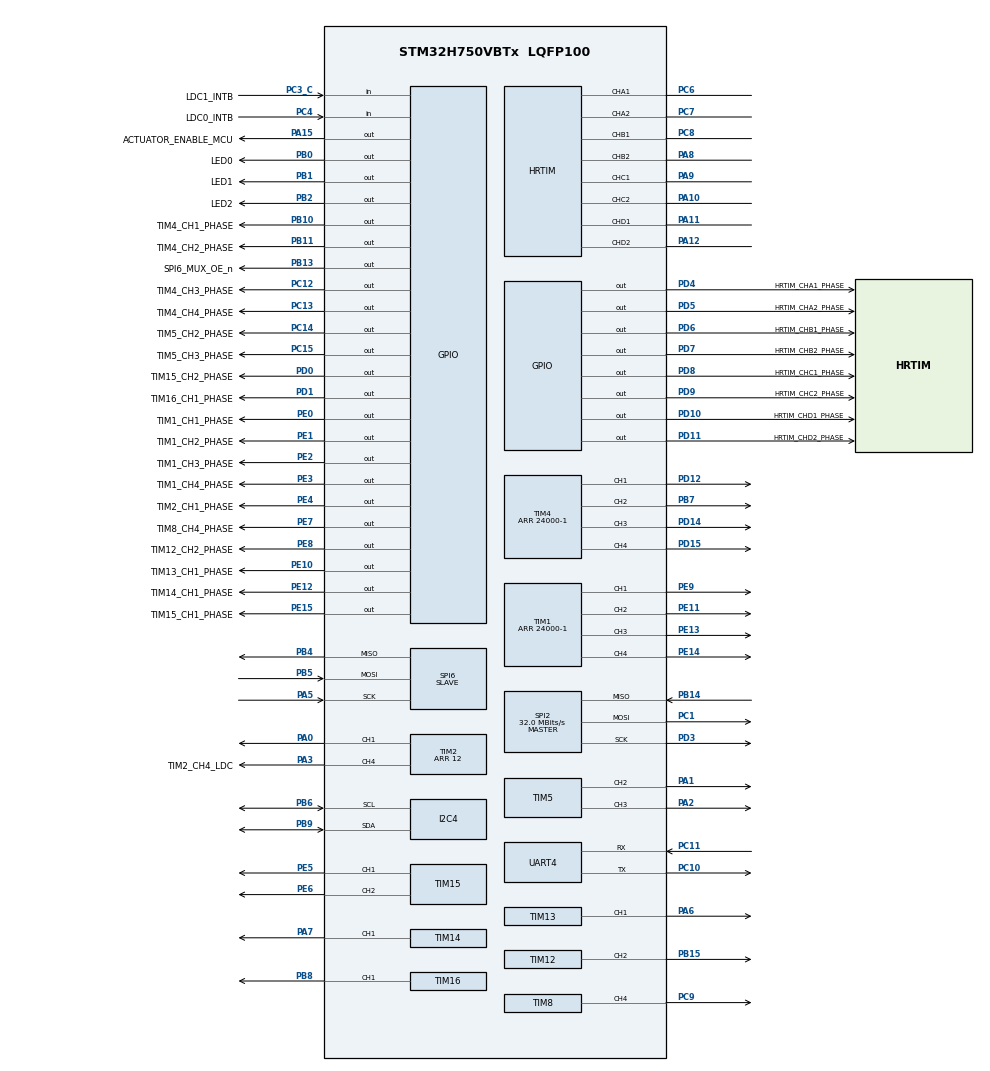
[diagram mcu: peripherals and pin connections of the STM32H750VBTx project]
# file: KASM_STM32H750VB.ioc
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HRTIM.Configuration_TD=Simple
HRTIM.Configuration_TE=Simple
HRTIM.PWMChannel_TD1=HRTIM_OUTPUT_TD1
HRTIM.Periode_TE=0xFF00
I2C4.Timing=0x307075B1
Mcu.Family=STM32H7
Mcu.Name=STM32H750VBTx
Mcu.Package=LQFP100
NVIC.PriorityGroup=NVIC_PRIORITYGROUP_4
NVIC.TIM1_UP_IRQn=true\:0\:0\:false\:false\:true\:true\:true\:true
PA0.Signal=S_TIM2_CH1_ETR
PA1.Signal=S_TIM5_CH2
PA10.Mode=Output_TC1TC2
PA10.Signal=HRTIM_CHC2
PA11.Mode=Output_TD1TD2
PA11.Signal=HRTIM_CHD1
PA12.Mode=Output_TD1TD2
PA12.Signal=HRTIM_CHD2
PA13\ (JTMS/SWDIO).Mode=Trace_Asynchronous_SW
PA13\ (JTMS/SWDIO).Signal=DEBUG_JTMS-SWDIO
PA14\ (JTCK/SWCLK).Mode=Trace_Asynchronous_SW
PA14\ (JTCK/SWCLK).Signal=DEBUG_JTCK-SWCLK
PA15\ (JTDI).GPIO_Label=ACTUATOR_ENABLE_MCU
PA15\ (JTDI).Signal=GPIO_Output
PA2.Signal=S_TIM5_CH3
PA3.GPIO_Label=TIM2_CH4_LDC
PA3.Signal=S_TIM2_CH4
PA4.Signal=SPI6_NSS
PA5.Mode=Full_Duplex_Slave
PA5.Signal=SPI6_SCK
PA6.Signal=S_TIM13_CH1
PA7.Signal=S_TIM14_CH1
PA8.Mode=Output_TB1TB2
PA8.Signal=HRTIM_CHB2
PA9.Mode=Output_TC1TC2
PA9.Signal=HRTIM_CHC1
PB0.GPIO_Label=LED0
PB0.Signal=GPIO_Output
PB1.GPIO_Label=LED1
PB1.Signal=GPIO_Output
PB10.GPIO_Label=TIM4_CH1_PHASE
PB10.Signal=GPIO_Output
PB11.GPIO_Label=TIM4_CH2_PHASE
PB11.Signal=GPIO_Output
PB12.Signal=SPI2_NSS
PB13.GPIO_Label=SPI6_MUX_OE_n
PB13.Signal=GPIO_Output
PB14.Mode=Full_Duplex_Master
PB14.Signal=SPI2_MISO
PB15.Signal=S_TIM12_CH2
PB2.GPIO_Label=LED2
PB2.Signal=GPIO_Output
PB3\ (JTDO/TRACESWO).Mode=Trace_Asynchronous_SW
PB3\ (JTDO/TRACESWO).Signal=DEBUG_JTDO-SWO
PB4\ (NJTRST).Mode=Full_Duplex_Slave
PB4\ (NJTRST).Signal=SPI6_MISO
PB5.Mode=Full_Duplex_Slave
PB5.Signal=SPI6_MOSI
PB6.Mode=I2C
PB6.Signal=I2C4_SCL
PB7.Signal=S_TIM4_CH2
PB8.Signal=S_TIM16_CH1
PB9.Mode=I2C
PB9.Signal=I2C4_SDA
PC0.Signal=ADCx_INP10
PC1.Mode=Full_Duplex_Master
PC1.Signal=SPI2_MOSI
PC10.Mode=Asynchronous
PC10.Signal=UART4_TX
PC11.Mode=Asynchronous
PC11.Signal=UART4_RX
PC12.GPIO_Label=TIM4_CH3_PHASE
PC12.Signal=GPIO_Output
PC13.GPIO_Label=TIM4_CH4_PHASE
PC13.Signal=GPIO_Output
PC14-OSC32_IN\ (OSC32_IN).GPIO_Label=TIM5_CH2_PHASE
PC14-OSC32_IN\ (OSC32_IN).Signal=GPIO_Output
PC15-OSC32_OUT\ (OSC32_OUT).GPIO_Label=TIM5_CH3_PHASE
PC15-OSC32_OUT\ (OSC32_OUT).Signal=GPIO_Output
PC3_C.GPIO_Label=LDC1_INTB
PC3_C.Signal=GPIO_Input
PC4.GPIO_Label=LDC0_INTB
PC4.Signal=GPIO_Input
PC6.Mode=Output_TA1TA2
PC6.Signal=HRTIM_CHA1
PC7.Mode=Output_TA1TA2
PC7.Signal=HRTIM_CHA2
PC8.Mode=Output_TB1TB2
PC8.Signal=HRTIM_CHB1
PC9.Signal=S_TIM8_CH4
PD0.GPIO_Label=TIM15_CH2_PHASE
PD0.Signal=GPIO_Output
PD1.GPIO_Label=TIM16_CH1_PHASE
PD1.Signal=GPIO_Output
PD10.GPIO_Label=HRTIM_CHD1_PHASE
PD10.Signal=GPIO_Output
PD11.GPIO_Label=HRTIM_CHD2_PHASE
PD11.Signal=GPIO_Output
PD12.Signal=S_TIM4_CH1
PD14.Signal=S_TIM4_CH3
PD15.Signal=S_TIM4_CH4
PD3.Mode=Full_Duplex_Master
PD3.Signal=SPI2_SCK
PD4.GPIO_Label=HRTIM_CHA1_PHASE
PD4.Signal=GPIO_Output
PD5.GPIO_Label=HRTIM_CHA2_PHASE
PD5.Signal=GPIO_Output
PD6.GPIO_Label=HRTIM_CHB1_PHASE
PD6.Signal=GPIO_Output
PD7.GPIO_Label=HRTIM_CHB2_PHASE
PD7.Signal=GPIO_Output
PD8.GPIO_Label=HRTIM_CHC1_PHASE
PD8.Signal=GPIO_Output
PD9.GPIO_Label=HRTIM_CHC2_PHASE
PD9.Signal=GPIO_Output
PE0.GPIO_Label=TIM1_CH1_PHASE
PE0.Signal=GPIO_Output
PE1.GPIO_Label=TIM1_CH2_PHASE
PE1.Signal=GPIO_Output
PE10.GPIO_Label=TIM13_CH1_PHASE
PE10.Signal=GPIO_Output
PE11.Signal=S_TIM1_CH2
PE12.GPIO_Label=TIM14_CH1_PHASE
PE12.Signal=GPIO_Output
PE13.Signal=S_TIM1_CH3
PE14.Signal=S_TIM1_CH4
PE15.GPIO_Label=TIM15_CH1_PHASE
PE15.Signal=GPIO_Output
PE2.GPIO_Label=TIM1_CH3_PHASE
PE2.Signal=GPIO_Output
PE3.GPIO_Label=TIM1_CH4_PHASE
PE3.Signal=GPIO_Output
PE4.GPIO_Label=TIM2_CH1_PHASE
PE4.Signal=GPIO_Output
PE5.Signal=S_TIM15_CH1
PE6.Signal=S_TIM15_CH2
PE7.GPIO_Label=TIM8_CH4_PHASE
PE7.Signal=GPIO_Output
PE8.GPIO_Label=TIM12_CH2_PHASE
PE8.Signal=GPIO_Output
PE9.Signal=S_TIM1_CH1
PH0-OSC_IN\ (PH0).Mode=HSE-External-Oscillator
PH0-OSC_IN\ (PH0).Signal=RCC_OSC_IN
PH1-OSC_OUT\ (PH1).Mode=HSE-External-Oscillator
PH1-OSC_OUT\ (PH1).Signal=RCC_OSC_OUT
ProjectManager.HeapSize=0x200
ProjectManager.StackSize=0x400
ProjectManager.TargetToolchain=STM32CubeIDE
RCC.ADCFreq_Value=75000000
RCC.APB1Freq_Value=120000000
RCC.APB2Freq_Value=120000000
RCC.APB3Freq_Value=120000000
RCC.APB4Freq_Value=120000000
RCC.CortexFreq_Value=480000000
RCC.D1PPRE=RCC_APB3_DIV2
RCC.D2PPRE1=RCC_APB1_DIV2
RCC.D2PPRE2=RCC_APB2_DIV2
RCC.D3PPRE=RCC_APB4_DIV2
RCC.DIVM1=2
RCC.DIVM2=2
RCC.DIVN1=80
RCC.DIVN2=12
RCC.DIVQ1=15
RCC.HCLKFreq_Value=240000000
RCC.HPRE=RCC_HCLK_DIV2
RCC.HSE_VALUE=24000000
RCC.PLL2FRACN=4096
RCC.PLL3FRACN=0
RCC.PLLFRACN=0
RCC.PLLSourceVirtual=RCC_PLLSOURCE_HSE
RCC.SYSCLKFreq_VALUE=480000000
RCC.SYSCLKSource=RCC_SYSCLKSOURCE_PLLCLK
RCC.USBFreq_Value=64000000
SH.ADCx_INP10.0=ADC2_INP10
SH.S_TIM12_CH2.0=TIM12_CH2,PWM Generation2 CH2
SH.S_TIM13_CH1.0=TIM13_CH1,PWM Generation1 CH1
SH.S_TIM14_CH1.0=TIM14_CH1,PWM Generation1 CH1
SH.S_TIM15_CH1.0=TIM15_CH1,PWM Generation1 CH1
SH.S_TIM15_CH2.0=TIM15_CH2,PWM Generation2 CH2
SH.S_TIM16_CH1.0=TIM16_CH1,PWM Generation1 CH1
SH.S_TIM1_CH1.0=TIM1_CH1,PWM Generation1 CH1
SH.S_TIM1_CH2.0=TIM1_CH2,PWM Generation2 CH2
SH.S_TIM1_CH3.0=TIM1_CH3,PWM Generation3 CH3
SH.S_TIM1_CH4.0=TIM1_CH4,PWM Generation4 CH4
SH.S_TIM2_CH1_ETR.0=TIM2_CH1,PWM Generation1 CH1
SH.S_TIM2_CH4.0=TIM2_CH4,PWM Generation4 CH4
SH.S_TIM4_CH1.0=TIM4_CH1,PWM Generation1 CH1
SH.S_TIM4_CH2.0=TIM4_CH2,PWM Generation2 CH2
SH.S_TIM4_CH3.0=TIM4_CH3,PWM Generation3 CH3
SH.S_TIM4_CH4.0=TIM4_CH4,PWM Generation4 CH4
SH.S_TIM5_CH2.0=TIM5_CH2,PWM Generation2 CH2
SH.S_TIM5_CH3.0=TIM5_CH3,PWM Generation3 CH3
SH.S_TIM8_CH4.0=TIM8_CH4,PWM Generation4 CH4
SPI2.CalculateBaudRate=32.0 MBits/s
SPI2.Direction=SPI_DIRECTION_2LINES
SPI2.Mode=SPI_MODE_MASTER
SPI2.VirtualType=VM_MASTER
SPI6.DataSize=SPI_DATASIZE_16BIT
SPI6.Direction=SPI_DIRECTION_2LINES
SPI6.Mode=SPI_MODE_SLAVE
SPI6.VirtualType=VM_SLAVE
TIM1.Channel-PWM\ Generation1\ CH1=TIM_CHANNEL_1
TIM1.Channel-PWM\ Generation2\ CH2=TIM_CHANNEL_2
TIM1.Channel-PWM\ Generation3\ CH3=TIM_CHANNEL_3
TIM1.Channel-PWM\ Generation4\ CH4=TIM_CHANNEL_4
TIM1.Period=24000-1
TIM12.Channel-PWM\ Generation2\ CH2=TIM_CHANNEL_2
TIM13.Channel=TIM_CHANNEL_1
TIM14.Channel=TIM_CHANNEL_1
TIM15.Channel-PWM\ Generation1\ CH1=TIM_CHANNEL_1
TIM15.Channel-PWM\ Generation2\ CH2=TIM_CHANNEL_2
TIM16.Channel=TIM_CHANNEL_1
TIM2.Channel-PWM\ Generation1\ CH1=TIM_CHANNEL_1
TIM2.Channel-PWM\ Generation4\ CH4=TIM_CHANNEL_4
TIM2.Period=12
TIM2.Pulse-PWM\ Generation1\ CH1=3
TIM2.Pulse-PWM\ Generation4\ CH4=6
TIM4.Channel-PWM\ Generation1\ CH1=TIM_CHANNEL_1
TIM4.Channel-PWM\ Generation2\ CH2=TIM_CHANNEL_2
TIM4.Channel-PWM\ Generation3\ CH3=TIM_CHANNEL_3
TIM4.Channel-PWM\ Generation4\ CH4=TIM_CHANNEL_4
TIM4.Period=24000-1
TIM5.Channel-PWM\ Generation2\ CH2=TIM_CHANNEL_2
TIM5.Channel-PWM\ Generation3\ CH3=TIM_CHANNEL_3
TIM8.Channel-PWM\ Generation4\ CH4=TIM_CHANNEL_4
VP_HRTIM_VS_hrtimMasterTimerNoOutput.Mode=MasterTimer
VP_HRTIM_VS_hrtimTimerENoOutput.Mode=No_output_TE
VP_LPTIM1_VS_LPTIM_counterModeInternalClock.Mode=Counts__internal_clock_event_00
VP_LPTIM2_VS_LPTIM_counterModeInternalClock.Mode=Counts__internal_clock_event_00
VP_LPTIM3_VS_LPTIM_counterModeInternalClock.Mode=Counts__internal_clock_event_00
VP_TIM13_VS_ClockSourceINT.Mode=Enable_Timer
VP_TIM14_VS_ClockSourceINT.Mode=Enable_Timer
VP_TIM16_VS_ClockSourceINT.Mode=Enable_Timer
VP_TIM1_VS_ClockSourceINT.Mode=Internal
VP_TIM4_VS_ClockSourceINT.Mode=Internal
board=custom

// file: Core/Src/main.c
/* USER CODE BEGIN Header */
/**
  ******************************************************************************
  * @file           : main.c
  * @brief          : Main program body
  ******************************************************************************
  * @attention
  *
  * Copyright (c) 2024 STMicroelectronics.
  * All rights reserved.
  *
  * This software is licensed under terms that can be found in the LICENSE file
  * in the root directory of this software component.
  * If no LICENSE file comes with this software, it is provided AS-IS.
  *
  ******************************************************************************
  */
/* USER CODE END Header */
#include "main.h"

/* USER CODE BEGIN Includes */
#include "ldc1614.h"

/* USER CODE END Includes */

/* USER CODE BEGIN PD */

#define PERIOD 24000
//Converts timer ticks to time scaling factor
#define PERIOD_SCALE (1.0/24000)
#define TICK_SCALE (1.0/240000000)

//Circular buffer characteristics
#define BUFFER_LENGTH 2048
#define MESSAGE_LENGTH 128

//Parameters for sorting/storing actuator commands
#define CMD_LENGTH 26*2
#define NUM_ACTUATORS 26

#define TRUE 1
#define FALSE 0
#define ONESEC 10000
#define TWOSEC 20000

/* USER CODE END PD */

HRTIM_HandleTypeDef hhrtim;

I2C_HandleTypeDef hi2c4;

LPTIM_HandleTypeDef hlptim1;
LPTIM_HandleTypeDef hlptim2;
LPTIM_HandleTypeDef hlptim3;

SPI_HandleTypeDef hspi2;
SPI_HandleTypeDef hspi6;

TIM_HandleTypeDef htim1;
TIM_HandleTypeDef htim2;
TIM_HandleTypeDef htim4;
TIM_HandleTypeDef htim5;
TIM_HandleTypeDef htim8;
TIM_HandleTypeDef htim12;
TIM_HandleTypeDef htim13;
TIM_HandleTypeDef htim14;
TIM_HandleTypeDef htim15;
TIM_HandleTypeDef htim16;

UART_HandleTypeDef huart4;

/* USER CODE BEGIN PV */

static const double VSS = 1.8; // fixed by PCB design
uint8_t ctrl_tmr_expired = FALSE; //controller update flag
static double ref=0;// reference (input) for control loop

/* USER CODE END PV */

void SystemClock_Config(void);
static void MX_GPIO_Init(void);
static void MX_HRTIM_Init(void);
static void MX_I2C4_Init(void);
static void MX_LPTIM1_Init(void);
static void MX_LPTIM2_Init(void);
static void MX_LPTIM3_Init(void);
static void MX_SPI2_Init(void);
static void MX_TIM1_Init(void);
static void MX_TIM2_Init(void);
static void MX_TIM4_Init(void);
static void MX_TIM5_Init(void);
static void MX_TIM8_Init(void);
static void MX_TIM12_Init(void);
static void MX_TIM13_Init(void);
static void MX_TIM14_Init(void);
static void MX_TIM15_Init(void);
static void MX_TIM16_Init(void);
static void MX_UART4_Init(void);
static void MX_SPI6_Init(void);
/* USER CODE BEGIN PFP */
static void control_update(double ref);
static uint16_t calc_dutycycle(double cmd, double vss);

/* USER CODE END PFP */

int main(void)
{

  /* USER CODE BEGIN 1 */
	int channel = 0;
	int L_uH = 72;
	int C_pF = 330;
	volatile uint32_t readings[NSAMPS] = {0};
	int ct = 0;
	int cycle_count = 0;

	uint8_t data[2] = {0};

	LDC1614 dev;

  /* USER CODE END 1 */

  /* MCU Configuration--------------------------------------------------------*/

  /* Reset of all peripherals, Initializes the Flash interface and the Systick. */
  HAL_Init();

  /* Configure the system clock */
  SystemClock_Config();

  /* Initialize all configured peripherals */
  MX_GPIO_Init();
  MX_HRTIM_Init();
  MX_I2C4_Init();
  MX_LPTIM1_Init();
  MX_LPTIM2_Init();
  MX_LPTIM3_Init();
  MX_SPI2_Init();
  MX_TIM1_Init();
  MX_TIM2_Init();
  MX_TIM4_Init();
  MX_TIM5_Init();
  MX_TIM8_Init();
  MX_TIM12_Init();
  MX_TIM13_Init();
  MX_TIM14_Init();
  MX_TIM15_Init();
  MX_TIM16_Init();
  MX_UART4_Init();
  MX_SPI6_Init();
  /* USER CODE BEGIN 2 */
  /* enable VSS */
  HAL_GPIO_WritePin(ACTUATOR_ENABLE_MCU_GPIO_Port, ACTUATOR_ENABLE_MCU_Pin, GPIO_PIN_SET);

  // Timer 1 initialization
  // Timer 1 serves as the main timer and is interrupted by period end
  HAL_TIM_Base_Start_IT(&htim1);
  HAL_TIM_PWM_Start(&htim1, TIM_CHANNEL_1);
  HAL_TIM_PWM_Start(&htim1, TIM_CHANNEL_2);
  HAL_TIM_PWM_Start(&htim1, TIM_CHANNEL_3);
  HAL_TIM_PWM_Start(&htim1, TIM_CHANNEL_4);
  HAL_GPIO_WritePin(TIM1_CH1_PHASE_GPIO_Port, TIM1_CH1_PHASE_Pin, GPIO_PIN_SET);
  HAL_GPIO_WritePin(TIM1_CH2_PHASE_GPIO_Port, TIM1_CH2_PHASE_Pin, GPIO_PIN_SET);
  HAL_GPIO_WritePin(TIM1_CH3_PHASE_GPIO_Port, TIM1_CH3_PHASE_Pin, GPIO_PIN_SET);
  HAL_GPIO_WritePin(TIM1_CH4_PHASE_GPIO_Port, TIM1_CH4_PHASE_Pin, GPIO_PIN_SET);

  //Timer 2 ch 4 is used as an oscillator for the eddy current sensor
  HAL_TIM_Base_Start(&htim2);
  HAL_TIM_PWM_Start(&htim2, TIM_CHANNEL_4);

  // End Timer 1

  ldc1614_init(&dev, &hi2c4, channel, L_uH, C_pF);

  ldc1614_read_reg(&dev, LDC1614_DEVICE_ID, data);
  ldc1614_read_reg(&dev, LDC1614_STATUS, data);

  /* USER CODE END 2 */

  /* Infinite loop */
  /* USER CODE BEGIN WHILE */
  while (1)
  {
	  if(ctrl_tmr_expired == TRUE) {
		  control_update(ref);
		  cycle_count += 1;
//		  if (cycle_count == 1000) {
//			  cycle_count = 0; // reset cycle counter

			  data[1] = 0;
			  ldc1614_read_reg(&dev, LDC1614_STATUS, data); // check for new data
			  if((data[1] & 0x08) !=0){ // if new data available
				  readings[ct] = ldc1614_get_ch0_reading(&dev); // get a sample
				  ct++; // increment sample counter
			  }
			  if(ct == NSAMPS) {
				  ct = 0; // reset sample counter
			  }
//		  }

	  }

    /* USER CODE END WHILE */

  }
}

void SystemClock_Config(void)
{
  RCC_OscInitTypeDef RCC_OscInitStruct = {0};
  RCC_ClkInitTypeDef RCC_ClkInitStruct = {0};

  /** Supply configuration update enable
  */
  HAL_PWREx_ConfigSupply(PWR_LDO_SUPPLY);

  /** Configure the main internal regulator output voltage
  */
  __HAL_PWR_VOLTAGESCALING_CONFIG(PWR_REGULATOR_VOLTAGE_SCALE1);

  while(!__HAL_PWR_GET_FLAG(PWR_FLAG_VOSRDY)) {}

  __HAL_RCC_SYSCFG_CLK_ENABLE();
  __HAL_PWR_VOLTAGESCALING_CONFIG(PWR_REGULATOR_VOLTAGE_SCALE0);

  while(!__HAL_PWR_GET_FLAG(PWR_FLAG_VOSRDY)) {}

  /** Initializes the RCC Oscillators according to the specified parameters
  * in the RCC_OscInitTypeDef structure.
  */
  RCC_OscInitStruct.OscillatorType = RCC_OSCILLATORTYPE_HSE;
  RCC_OscInitStruct.HSEState = RCC_HSE_ON;
  RCC_OscInitStruct.PLL.PLLState = RCC_PLL_ON;
  RCC_OscInitStruct.PLL.PLLSource = RCC_PLLSOURCE_HSE;
  RCC_OscInitStruct.PLL.PLLM = 2;
  RCC_OscInitStruct.PLL.PLLN = 80;
  RCC_OscInitStruct.PLL.PLLP = 2;
  RCC_OscInitStruct.PLL.PLLQ = 15;
  RCC_OscInitStruct.PLL.PLLR = 2;
  RCC_OscInitStruct.PLL.PLLRGE = RCC_PLL1VCIRANGE_3;
  RCC_OscInitStruct.PLL.PLLVCOSEL = RCC_PLL1VCOWIDE;
  RCC_OscInitStruct.PLL.PLLFRACN = 0;
  if (HAL_RCC_OscConfig(&RCC_OscInitStruct) != HAL_OK)
  {
    Error_Handler();
  }

  /** Initializes the CPU, AHB and APB buses clocks
  */
  RCC_ClkInitStruct.ClockType = RCC_CLOCKTYPE_HCLK|RCC_CLOCKTYPE_SYSCLK
                              |RCC_CLOCKTYPE_PCLK1|RCC_CLOCKTYPE_PCLK2
                              |RCC_CLOCKTYPE_D3PCLK1|RCC_CLOCKTYPE_D1PCLK1;
  RCC_ClkInitStruct.SYSCLKSource = RCC_SYSCLKSOURCE_PLLCLK;
  RCC_ClkInitStruct.SYSCLKDivider = RCC_SYSCLK_DIV1;
  RCC_ClkInitStruct.AHBCLKDivider = RCC_HCLK_DIV2;
  RCC_ClkInitStruct.APB3CLKDivider = RCC_APB3_DIV2;
  RCC_ClkInitStruct.APB1CLKDivider = RCC_APB1_DIV2;
  RCC_ClkInitStruct.APB2CLKDivider = RCC_APB2_DIV2;
  RCC_ClkInitStruct.APB4CLKDivider = RCC_APB4_DIV2;

  if (HAL_RCC_ClockConfig(&RCC_ClkInitStruct, FLASH_LATENCY_4) != HAL_OK)
  {
    Error_Handler();
  }
}

static void MX_HRTIM_Init(void)
{

  HRTIM_TimeBaseCfgTypeDef pTimeBaseCfg = {0};
  HRTIM_TimerCfgTypeDef pTimerCfg = {0};
  HRTIM_OutputCfgTypeDef pOutputCfg = {0};
  HRTIM_SimplePWMChannelCfgTypeDef pSimplePWMChannelCfg = {0};

  hhrtim.Instance = HRTIM1;
  hhrtim.Init.HRTIMInterruptResquests = HRTIM_IT_NONE;
  hhrtim.Init.SyncOptions = HRTIM_SYNCOPTION_NONE;
  if (HAL_HRTIM_Init(&hhrtim) != HAL_OK)
  {
    Error_Handler();
  }
  pTimeBaseCfg.Period = 0xFFFD;
  pTimeBaseCfg.RepetitionCounter = 0x00;
  pTimeBaseCfg.PrescalerRatio = HRTIM_PRESCALERRATIO_DIV1;
  pTimeBaseCfg.Mode = HRTIM_MODE_CONTINUOUS;
  if (HAL_HRTIM_TimeBaseConfig(&hhrtim, HRTIM_TIMERINDEX_MASTER, &pTimeBaseCfg) != HAL_OK)
  {
    Error_Handler();
  }
  pTimerCfg.InterruptRequests = HRTIM_MASTER_IT_NONE;
  pTimerCfg.DMARequests = HRTIM_MASTER_DMA_NONE;
  pTimerCfg.DMASrcAddress = 0x0000;
  pTimerCfg.DMADstAddress = 0x0000;
  pTimerCfg.DMASize = 0x1;
  pTimerCfg.HalfModeEnable = HRTIM_HALFMODE_DISABLED;
  pTimerCfg.StartOnSync = HRTIM_SYNCSTART_DISABLED;
  pTimerCfg.ResetOnSync = HRTIM_SYNCRESET_DISABLED;
  pTimerCfg.DACSynchro = HRTIM_DACSYNC_NONE;
  pTimerCfg.PreloadEnable = HRTIM_PRELOAD_DISABLED;
  pTimerCfg.UpdateGating = HRTIM_UPDATEGATING_INDEPENDENT;
  pTimerCfg.BurstMode = HRTIM_TIMERBURSTMODE_MAINTAINCLOCK;
  pTimerCfg.RepetitionUpdate = HRTIM_UPDATEONREPETITION_DISABLED;
  if (HAL_HRTIM_WaveformTimerConfig(&hhrtim, HRTIM_TIMERINDEX_MASTER, &pTimerCfg) != HAL_OK)
  {
    Error_Handler();
  }
  if (HAL_HRTIM_TimeBaseConfig(&hhrtim, HRTIM_TIMERINDEX_TIMER_A, &pTimeBaseCfg) != HAL_OK)
  {
    Error_Handler();
  }
  pTimerCfg.InterruptRequests = HRTIM_TIM_IT_NONE;
  pTimerCfg.DMARequests = HRTIM_TIM_DMA_NONE;
  pTimerCfg.PushPull = HRTIM_TIMPUSHPULLMODE_DISABLED;
  pTimerCfg.FaultEnable = HRTIM_TIMFAULTENABLE_NONE;
  pTimerCfg.FaultLock = HRTIM_TIMFAULTLOCK_READWRITE;
  pTimerCfg.DeadTimeInsertion = HRTIM_TIMDEADTIMEINSERTION_DISABLED;
  pTimerCfg.DelayedProtectionMode = HRTIM_TIMER_A_B_C_DELAYEDPROTECTION_DISABLED;
  pTimerCfg.UpdateTrigger = HRTIM_TIMUPDATETRIGGER_NONE;
  pTimerCfg.ResetTrigger = HRTIM_TIMRESETTRIGGER_NONE;
  pTimerCfg.ResetUpdate = HRTIM_TIMUPDATEONRESET_DISABLED;
  if (HAL_HRTIM_WaveformTimerConfig(&hhrtim, HRTIM_TIMERINDEX_TIMER_A, &pTimerCfg) != HAL_OK)
  {
    Error_Handler();
  }
  if (HAL_HRTIM_WaveformTimerConfig(&hhrtim, HRTIM_TIMERINDEX_TIMER_B, &pTimerCfg) != HAL_OK)
  {
    Error_Handler();
  }
  if (HAL_HRTIM_WaveformTimerConfig(&hhrtim, HRTIM_TIMERINDEX_TIMER_C, &pTimerCfg) != HAL_OK)
  {
    Error_Handler();
  }
  pOutputCfg.Polarity = HRTIM_OUTPUTPOLARITY_HIGH;
  pOutputCfg.SetSource = HRTIM_OUTPUTSET_NONE;
  pOutputCfg.ResetSource = HRTIM_OUTPUTRESET_NONE;
  pOutputCfg.IdleMode = HRTIM_OUTPUTIDLEMODE_NONE;
  pOutputCfg.IdleLevel = HRTIM_OUTPUTIDLELEVEL_INACTIVE;
  pOutputCfg.FaultLevel = HRTIM_OUTPUTFAULTLEVEL_NONE;
  pOutputCfg.ChopperModeEnable = HRTIM_OUTPUTCHOPPERMODE_DISABLED;
  pOutputCfg.BurstModeEntryDelayed = HRTIM_OUTPUTBURSTMODEENTRY_REGULAR;
  if (HAL_HRTIM_WaveformOutputConfig(&hhrtim, HRTIM_TIMERINDEX_TIMER_A, HRTIM_OUTPUT_TA1, &pOutputCfg) != HAL_OK)
  {
    Error_Handler();
  }
  if (HAL_HRTIM_WaveformOutputConfig(&hhrtim, HRTIM_TIMERINDEX_TIMER_B, HRTIM_OUTPUT_TB1, &pOutputCfg) != HAL_OK)
  {
    Error_Handler();
  }
  if (HAL_HRTIM_WaveformOutputConfig(&hhrtim, HRTIM_TIMERINDEX_TIMER_C, HRTIM_OUTPUT_TC1, &pOutputCfg) != HAL_OK)
  {
    Error_Handler();
  }
  if (HAL_HRTIM_WaveformOutputConfig(&hhrtim, HRTIM_TIMERINDEX_TIMER_A, HRTIM_OUTPUT_TA2, &pOutputCfg) != HAL_OK)
  {
    Error_Handler();
  }
  if (HAL_HRTIM_WaveformOutputConfig(&hhrtim, HRTIM_TIMERINDEX_TIMER_B, HRTIM_OUTPUT_TB2, &pOutputCfg) != HAL_OK)
  {
    Error_Handler();
  }
  if (HAL_HRTIM_WaveformOutputConfig(&hhrtim, HRTIM_TIMERINDEX_TIMER_C, HRTIM_OUTPUT_TC2, &pOutputCfg) != HAL_OK)
  {
    Error_Handler();
  }
  if (HAL_HRTIM_TimeBaseConfig(&hhrtim, HRTIM_TIMERINDEX_TIMER_B, &pTimeBaseCfg) != HAL_OK)
  {
    Error_Handler();
  }
  if (HAL_HRTIM_TimeBaseConfig(&hhrtim, HRTIM_TIMERINDEX_TIMER_C, &pTimeBaseCfg) != HAL_OK)
  {
    Error_Handler();
  }
  if (HAL_HRTIM_TimeBaseConfig(&hhrtim, HRTIM_TIMERINDEX_TIMER_D, &pTimeBaseCfg) != HAL_OK)
  {
    Error_Handler();
  }
  pSimplePWMChannelCfg.Pulse = 0xFFFD;
  pSimplePWMChannelCfg.Polarity = HRTIM_OUTPUTPOLARITY_HIGH;
  pSimplePWMChannelCfg.IdleLevel = HRTIM_OUTPUTIDLELEVEL_INACTIVE;
  if (HAL_HRTIM_SimplePWMChannelConfig(&hhrtim, HRTIM_TIMERINDEX_TIMER_D, HRTIM_OUTPUT_TD1, &pSimplePWMChannelCfg) != HAL_OK)
  {
    Error_Handler();
  }
  pTimeBaseCfg.Period = 0xFF00;
  if (HAL_HRTIM_TimeBaseConfig(&hhrtim, HRTIM_TIMERINDEX_TIMER_E, &pTimeBaseCfg) != HAL_OK)
  {
    Error_Handler();
  }
  HAL_HRTIM_MspPostInit(&hhrtim);

}

static void MX_I2C4_Init(void)
{

  hi2c4.Instance = I2C4;
  hi2c4.Init.Timing = 0x307075B1;
  hi2c4.Init.OwnAddress1 = 0;
  hi2c4.Init.AddressingMode = I2C_ADDRESSINGMODE_7BIT;
  hi2c4.Init.DualAddressMode = I2C_DUALADDRESS_DISABLE;
  hi2c4.Init.OwnAddress2 = 0;
  hi2c4.Init.OwnAddress2Masks = I2C_OA2_NOMASK;
  hi2c4.Init.GeneralCallMode = I2C_GENERALCALL_DISABLE;
  hi2c4.Init.NoStretchMode = I2C_NOSTRETCH_DISABLE;
  if (HAL_I2C_Init(&hi2c4) != HAL_OK)
  {
    Error_Handler();
  }

  /** Configure Analogue filter
  */
  if (HAL_I2CEx_ConfigAnalogFilter(&hi2c4, I2C_ANALOGFILTER_ENABLE) != HAL_OK)
  {
    Error_Handler();
  }

  /** Configure Digital filter
  */
  if (HAL_I2CEx_ConfigDigitalFilter(&hi2c4, 0) != HAL_OK)
  {
    Error_Handler();
  }

}

static void MX_LPTIM1_Init(void)
{

  hlptim1.Instance = LPTIM1;
  hlptim1.Init.Clock.Source = LPTIM_CLOCKSOURCE_APBCLOCK_LPOSC;
  hlptim1.Init.Clock.Prescaler = LPTIM_PRESCALER_DIV1;
  hlptim1.Init.Trigger.Source = LPTIM_TRIGSOURCE_SOFTWARE;
  hlptim1.Init.OutputPolarity = LPTIM_OUTPUTPOLARITY_HIGH;
  hlptim1.Init.UpdateMode = LPTIM_UPDATE_IMMEDIATE;
  hlptim1.Init.CounterSource = LPTIM_COUNTERSOURCE_INTERNAL;
  hlptim1.Init.Input1Source = LPTIM_INPUT1SOURCE_GPIO;
  hlptim1.Init.Input2Source = LPTIM_INPUT2SOURCE_GPIO;
  if (HAL_LPTIM_Init(&hlptim1) != HAL_OK)
  {
    Error_Handler();
  }

}

static void MX_LPTIM2_Init(void)
{

  hlptim2.Instance = LPTIM2;
  hlptim2.Init.Clock.Source = LPTIM_CLOCKSOURCE_APBCLOCK_LPOSC;
  hlptim2.Init.Clock.Prescaler = LPTIM_PRESCALER_DIV1;
  hlptim2.Init.Trigger.Source = LPTIM_TRIGSOURCE_SOFTWARE;
  hlptim2.Init.OutputPolarity = LPTIM_OUTPUTPOLARITY_HIGH;
  hlptim2.Init.UpdateMode = LPTIM_UPDATE_IMMEDIATE;
  hlptim2.Init.CounterSource = LPTIM_COUNTERSOURCE_INTERNAL;
  hlptim2.Init.Input1Source = LPTIM_INPUT1SOURCE_GPIO;
  hlptim2.Init.Input2Source = LPTIM_INPUT2SOURCE_GPIO;
  if (HAL_LPTIM_Init(&hlptim2) != HAL_OK)
  {
    Error_Handler();
  }

}

static void MX_LPTIM3_Init(void)
{

  hlptim3.Instance = LPTIM3;
  hlptim3.Init.Clock.Source = LPTIM_CLOCKSOURCE_APBCLOCK_LPOSC;
  hlptim3.Init.Clock.Prescaler = LPTIM_PRESCALER_DIV1;
  hlptim3.Init.Trigger.Source = LPTIM_TRIGSOURCE_SOFTWARE;
  hlptim3.Init.OutputPolarity = LPTIM_OUTPUTPOLARITY_HIGH;
  hlptim3.Init.UpdateMode = LPTIM_UPDATE_IMMEDIATE;
  hlptim3.Init.CounterSource = LPTIM_COUNTERSOURCE_INTERNAL;
  hlptim3.Init.Input1Source = LPTIM_INPUT1SOURCE_GPIO;
  if (HAL_LPTIM_Init(&hlptim3) != HAL_OK)
  {
    Error_Handler();
  }

}

static void MX_SPI2_Init(void)
{

  /* SPI2 parameter configuration*/
  hspi2.Instance = SPI2;
  hspi2.Init.Mode = SPI_MODE_MASTER;
  hspi2.Init.Direction = SPI_DIRECTION_2LINES;
  hspi2.Init.DataSize = SPI_DATASIZE_4BIT;
  hspi2.Init.CLKPolarity = SPI_POLARITY_LOW;
  hspi2.Init.CLKPhase = SPI_PHASE_1EDGE;
  hspi2.Init.NSS = SPI_NSS_SOFT;
  hspi2.Init.BaudRatePrescaler = SPI_BAUDRATEPRESCALER_2;
  hspi2.Init.FirstBit = SPI_FIRSTBIT_MSB;
  hspi2.Init.TIMode = SPI_TIMODE_DISABLE;
  hspi2.Init.CRCCalculation = SPI_CRCCALCULATION_DISABLE;
  hspi2.Init.CRCPolynomial = 0x0;
  hspi2.Init.NSSPMode = SPI_NSS_PULSE_ENABLE;
  hspi2.Init.NSSPolarity = SPI_NSS_POLARITY_LOW;
  hspi2.Init.FifoThreshold = SPI_FIFO_THRESHOLD_01DATA;
  hspi2.Init.TxCRCInitializationPattern = SPI_CRC_INITIALIZATION_ALL_ZERO_PATTERN;
  hspi2.Init.RxCRCInitializationPattern = SPI_CRC_INITIALIZATION_ALL_ZERO_PATTERN;
  hspi2.Init.MasterSSIdleness = SPI_MASTER_SS_IDLENESS_00CYCLE;
  hspi2.Init.MasterInterDataIdleness = SPI_MASTER_INTERDATA_IDLENESS_00CYCLE;
  hspi2.Init.MasterReceiverAutoSusp = SPI_MASTER_RX_AUTOSUSP_DISABLE;
  hspi2.Init.MasterKeepIOState = SPI_MASTER_KEEP_IO_STATE_DISABLE;
  hspi2.Init.IOSwap = SPI_IO_SWAP_DISABLE;
  if (HAL_SPI_Init(&hspi2) != HAL_OK)
  {
    Error_Handler();
  }

}

static void MX_SPI6_Init(void)
{

  /* SPI6 parameter configuration*/
  hspi6.Instance = SPI6;
  hspi6.Init.Mode = SPI_MODE_SLAVE;
  hspi6.Init.Direction = SPI_DIRECTION_2LINES;
  hspi6.Init.DataSize = SPI_DATASIZE_16BIT;
  hspi6.Init.CLKPolarity = SPI_POLARITY_LOW;
  hspi6.Init.CLKPhase = SPI_PHASE_1EDGE;
  hspi6.Init.NSS = SPI_NSS_SOFT;
  hspi6.Init.FirstBit = SPI_FIRSTBIT_MSB;
  hspi6.Init.TIMode = SPI_TIMODE_DISABLE;
  hspi6.Init.CRCCalculation = SPI_CRCCALCULATION_DISABLE;
  hspi6.Init.CRCPolynomial = 0x0;
  hspi6.Init.NSSPMode = SPI_NSS_PULSE_DISABLE;
  hspi6.Init.NSSPolarity = SPI_NSS_POLARITY_LOW;
  hspi6.Init.FifoThreshold = SPI_FIFO_THRESHOLD_01DATA;
  hspi6.Init.TxCRCInitializationPattern = SPI_CRC_INITIALIZATION_ALL_ZERO_PATTERN;
  hspi6.Init.RxCRCInitializationPattern = SPI_CRC_INITIALIZATION_ALL_ZERO_PATTERN;
  hspi6.Init.MasterSSIdleness = SPI_MASTER_SS_IDLENESS_00CYCLE;
  hspi6.Init.MasterInterDataIdleness = SPI_MASTER_INTERDATA_IDLENESS_00CYCLE;
  hspi6.Init.MasterReceiverAutoSusp = SPI_MASTER_RX_AUTOSUSP_DISABLE;
  hspi6.Init.MasterKeepIOState = SPI_MASTER_KEEP_IO_STATE_DISABLE;
  hspi6.Init.IOSwap = SPI_IO_SWAP_DISABLE;
  if (HAL_SPI_Init(&hspi6) != HAL_OK)
  {
    Error_Handler();
  }

}

static void MX_TIM1_Init(void)
{

  TIM_ClockConfigTypeDef sClockSourceConfig = {0};
  TIM_MasterConfigTypeDef sMasterConfig = {0};
  TIM_OC_InitTypeDef sConfigOC = {0};
  TIM_BreakDeadTimeConfigTypeDef sBreakDeadTimeConfig = {0};

  htim1.Instance = TIM1;
  htim1.Init.Prescaler = 0;
  htim1.Init.CounterMode = TIM_COUNTERMODE_UP;
  htim1.Init.Period = 24000-1;
  htim1.Init.ClockDivision = TIM_CLOCKDIVISION_DIV1;
  htim1.Init.RepetitionCounter = 0;
  htim1.Init.AutoReloadPreload = TIM_AUTORELOAD_PRELOAD_DISABLE;
  if (HAL_TIM_Base_Init(&htim1) != HAL_OK)
  {
    Error_Handler();
  }
  sClockSourceConfig.ClockSource = TIM_CLOCKSOURCE_INTERNAL;
  if (HAL_TIM_ConfigClockSource(&htim1, &sClockSourceConfig) != HAL_OK)
  {
    Error_Handler();
  }
  if (HAL_TIM_PWM_Init(&htim1) != HAL_OK)
  {
    Error_Handler();
  }
  sMasterConfig.MasterOutputTrigger = TIM_TRGO_RESET;
  sMasterConfig.MasterOutputTrigger2 = TIM_TRGO2_RESET;
  sMasterConfig.MasterSlaveMode = TIM_MASTERSLAVEMODE_DISABLE;
  if (HAL_TIMEx_MasterConfigSynchronization(&htim1, &sMasterConfig) != HAL_OK)
  {
    Error_Handler();
  }
  sConfigOC.OCMode = TIM_OCMODE_PWM1;
  sConfigOC.Pulse = 0;
  sConfigOC.OCPolarity = TIM_OCPOLARITY_HIGH;
  sConfigOC.OCNPolarity = TIM_OCNPOLARITY_HIGH;
  sConfigOC.OCFastMode = TIM_OCFAST_DISABLE;
  sConfigOC.OCIdleState = TIM_OCIDLESTATE_RESET;
  sConfigOC.OCNIdleState = TIM_OCNIDLESTATE_RESET;
  if (HAL_TIM_PWM_ConfigChannel(&htim1, &sConfigOC, TIM_CHANNEL_1) != HAL_OK)
  {
    Error_Handler();
  }
  if (HAL_TIM_PWM_ConfigChannel(&htim1, &sConfigOC, TIM_CHANNEL_2) != HAL_OK)
  {
    Error_Handler();
  }
  if (HAL_TIM_PWM_ConfigChannel(&htim1, &sConfigOC, TIM_CHANNEL_3) != HAL_OK)
  {
    Error_Handler();
  }
  if (HAL_TIM_PWM_ConfigChannel(&htim1, &sConfigOC, TIM_CHANNEL_4) != HAL_OK)
  {
    Error_Handler();
  }
  sBreakDeadTimeConfig.OffStateRunMode = TIM_OSSR_DISABLE;
  sBreakDeadTimeConfig.OffStateIDLEMode = TIM_OSSI_DISABLE;
  sBreakDeadTimeConfig.LockLevel = TIM_LOCKLEVEL_OFF;
  sBreakDeadTimeConfig.DeadTime = 0;
  sBreakDeadTimeConfig.BreakState = TIM_BREAK_DISABLE;
  sBreakDeadTimeConfig.BreakPolarity = TIM_BREAKPOLARITY_HIGH;
  sBreakDeadTimeConfig.BreakFilter = 0;
  sBreakDeadTimeConfig.Break2State = TIM_BREAK2_DISABLE;
  sBreakDeadTimeConfig.Break2Polarity = TIM_BREAK2POLARITY_HIGH;
  sBreakDeadTimeConfig.Break2Filter = 0;
  sBreakDeadTimeConfig.AutomaticOutput = TIM_AUTOMATICOUTPUT_DISABLE;
  if (HAL_TIMEx_ConfigBreakDeadTime(&htim1, &sBreakDeadTimeConfig) != HAL_OK)
  {
    Error_Handler();
  }
  HAL_TIM_MspPostInit(&htim1);

}

static void MX_TIM2_Init(void)
{

  TIM_MasterConfigTypeDef sMasterConfig = {0};
  TIM_OC_InitTypeDef sConfigOC = {0};

  htim2.Instance = TIM2;
  htim2.Init.Prescaler = 0;
  htim2.Init.CounterMode = TIM_COUNTERMODE_UP;
  htim2.Init.Period = 12;
  htim2.Init.ClockDivision = TIM_CLOCKDIVISION_DIV1;
  htim2.Init.AutoReloadPreload = TIM_AUTORELOAD_PRELOAD_DISABLE;
  if (HAL_TIM_PWM_Init(&htim2) != HAL_OK)
  {
    Error_Handler();
  }
  sMasterConfig.MasterOutputTrigger = TIM_TRGO_RESET;
  sMasterConfig.MasterSlaveMode = TIM_MASTERSLAVEMODE_DISABLE;
  if (HAL_TIMEx_MasterConfigSynchronization(&htim2, &sMasterConfig) != HAL_OK)
  {
    Error_Handler();
  }
  sConfigOC.OCMode = TIM_OCMODE_PWM1;
  sConfigOC.Pulse = 3;
  sConfigOC.OCPolarity = TIM_OCPOLARITY_HIGH;
  sConfigOC.OCFastMode = TIM_OCFAST_DISABLE;
  if (HAL_TIM_PWM_ConfigChannel(&htim2, &sConfigOC, TIM_CHANNEL_1) != HAL_OK)
  {
    Error_Handler();
  }
  sConfigOC.Pulse = 6;
  if (HAL_TIM_PWM_ConfigChannel(&htim2, &sConfigOC, TIM_CHANNEL_4) != HAL_OK)
  {
    Error_Handler();
  }
  HAL_TIM_MspPostInit(&htim2);

}

static void MX_TIM4_Init(void)
{

  TIM_ClockConfigTypeDef sClockSourceConfig = {0};
  TIM_MasterConfigTypeDef sMasterConfig = {0};
  TIM_OC_InitTypeDef sConfigOC = {0};

  htim4.Instance = TIM4;
  htim4.Init.Prescaler = 0;
  htim4.Init.CounterMode = TIM_COUNTERMODE_UP;
  htim4.Init.Period = 24000-1;
  htim4.Init.ClockDivision = TIM_CLOCKDIVISION_DIV1;
  htim4.Init.AutoReloadPreload = TIM_AUTORELOAD_PRELOAD_DISABLE;
  if (HAL_TIM_Base_Init(&htim4) != HAL_OK)
  {
    Error_Handler();
  }
  sClockSourceConfig.ClockSource = TIM_CLOCKSOURCE_INTERNAL;
  if (HAL_TIM_ConfigClockSource(&htim4, &sClockSourceConfig) != HAL_OK)
  {
    Error_Handler();
  }
  if (HAL_TIM_PWM_Init(&htim4) != HAL_OK)
  {
    Error_Handler();
  }
  sMasterConfig.MasterOutputTrigger = TIM_TRGO_RESET;
  sMasterConfig.MasterSlaveMode = TIM_MASTERSLAVEMODE_DISABLE;
  if (HAL_TIMEx_MasterConfigSynchronization(&htim4, &sMasterConfig) != HAL_OK)
  {
    Error_Handler();
  }
  sConfigOC.OCMode = TIM_OCMODE_PWM1;
  sConfigOC.Pulse = 0;
  sConfigOC.OCPolarity = TIM_OCPOLARITY_HIGH;
  sConfigOC.OCFastMode = TIM_OCFAST_DISABLE;
  if (HAL_TIM_PWM_ConfigChannel(&htim4, &sConfigOC, TIM_CHANNEL_1) != HAL_OK)
  {
    Error_Handler();
  }
  if (HAL_TIM_PWM_ConfigChannel(&htim4, &sConfigOC, TIM_CHANNEL_2) != HAL_OK)
  {
    Error_Handler();
  }
  if (HAL_TIM_PWM_ConfigChannel(&htim4, &sConfigOC, TIM_CHANNEL_3) != HAL_OK)
  {
    Error_Handler();
  }
  if (HAL_TIM_PWM_ConfigChannel(&htim4, &sConfigOC, TIM_CHANNEL_4) != HAL_OK)
  {
    Error_Handler();
  }
  HAL_TIM_MspPostInit(&htim4);

}

static void MX_TIM5_Init(void)
{

  TIM_MasterConfigTypeDef sMasterConfig = {0};
  TIM_OC_InitTypeDef sConfigOC = {0};

  htim5.Instance = TIM5;
  htim5.Init.Prescaler = 0;
  htim5.Init.CounterMode = TIM_COUNTERMODE_UP;
  htim5.Init.Period = 4294967295;
  htim5.Init.ClockDivision = TIM_CLOCKDIVISION_DIV1;
  htim5.Init.AutoReloadPreload = TIM_AUTORELOAD_PRELOAD_DISABLE;
  if (HAL_TIM_PWM_Init(&htim5) != HAL_OK)
  {
    Error_Handler();
  }
  sMasterConfig.MasterOutputTrigger = TIM_TRGO_RESET;
  sMasterConfig.MasterSlaveMode = TIM_MASTERSLAVEMODE_DISABLE;
  if (HAL_TIMEx_MasterConfigSynchronization(&htim5, &sMasterConfig) != HAL_OK)
  {
    Error_Handler();
  }
  sConfigOC.OCMode = TIM_OCMODE_PWM1;
  sConfigOC.Pulse = 0;
  sConfigOC.OCPolarity = TIM_OCPOLARITY_HIGH;
  sConfigOC.OCFastMode = TIM_OCFAST_DISABLE;
  if (HAL_TIM_PWM_ConfigChannel(&htim5, &sConfigOC, TIM_CHANNEL_2) != HAL_OK)
  {
    Error_Handler();
  }
  if (HAL_TIM_PWM_ConfigChannel(&htim5, &sConfigOC, TIM_CHANNEL_3) != HAL_OK)
  {
    Error_Handler();
  }
  HAL_TIM_MspPostInit(&htim5);

}

static void MX_TIM8_Init(void)
{

  TIM_MasterConfigTypeDef sMasterConfig = {0};
  TIM_OC_InitTypeDef sConfigOC = {0};
  TIM_BreakDeadTimeConfigTypeDef sBreakDeadTimeConfig = {0};

  htim8.Instance = TIM8;
  htim8.Init.Prescaler = 0;
  htim8.Init.CounterMode = TIM_COUNTERMODE_UP;
  htim8.Init.Period = 65535;
  htim8.Init.ClockDivision = TIM_CLOCKDIVISION_DIV1;
  htim8.Init.RepetitionCounter = 0;
  htim8.Init.AutoReloadPreload = TIM_AUTORELOAD_PRELOAD_DISABLE;
  if (HAL_TIM_PWM_Init(&htim8) != HAL_OK)
  {
    Error_Handler();
  }
  sMasterConfig.MasterOutputTrigger = TIM_TRGO_RESET;
  sMasterConfig.MasterOutputTrigger2 = TIM_TRGO2_RESET;
  sMasterConfig.MasterSlaveMode = TIM_MASTERSLAVEMODE_DISABLE;
  if (HAL_TIMEx_MasterConfigSynchronization(&htim8, &sMasterConfig) != HAL_OK)
  {
    Error_Handler();
  }
  sConfigOC.OCMode = TIM_OCMODE_PWM1;
  sConfigOC.Pulse = 0;
  sConfigOC.OCPolarity = TIM_OCPOLARITY_HIGH;
  sConfigOC.OCFastMode = TIM_OCFAST_DISABLE;
  sConfigOC.OCIdleState = TIM_OCIDLESTATE_RESET;
  sConfigOC.OCNIdleState = TIM_OCNIDLESTATE_RESET;
  if (HAL_TIM_PWM_ConfigChannel(&htim8, &sConfigOC, TIM_CHANNEL_4) != HAL_OK)
  {
    Error_Handler();
  }
  sBreakDeadTimeConfig.OffStateRunMode = TIM_OSSR_DISABLE;
  sBreakDeadTimeConfig.OffStateIDLEMode = TIM_OSSI_DISABLE;
  sBreakDeadTimeConfig.LockLevel = TIM_LOCKLEVEL_OFF;
  sBreakDeadTimeConfig.DeadTime = 0;
  sBreakDeadTimeConfig.BreakState = TIM_BREAK_DISABLE;
  sBreakDeadTimeConfig.BreakPolarity = TIM_BREAKPOLARITY_HIGH;
  sBreakDeadTimeConfig.BreakFilter = 0;
  sBreakDeadTimeConfig.Break2State = TIM_BREAK2_DISABLE;
  sBreakDeadTimeConfig.Break2Polarity = TIM_BREAK2POLARITY_HIGH;
  sBreakDeadTimeConfig.Break2Filter = 0;
  sBreakDeadTimeConfig.AutomaticOutput = TIM_AUTOMATICOUTPUT_DISABLE;
  if (HAL_TIMEx_ConfigBreakDeadTime(&htim8, &sBreakDeadTimeConfig) != HAL_OK)
  {
    Error_Handler();
  }
  HAL_TIM_MspPostInit(&htim8);

}

static void MX_TIM12_Init(void)
{

  TIM_MasterConfigTypeDef sMasterConfig = {0};
  TIM_OC_InitTypeDef sConfigOC = {0};

  htim12.Instance = TIM12;
  htim12.Init.Prescaler = 0;
  htim12.Init.CounterMode = TIM_COUNTERMODE_UP;
  htim12.Init.Period = 65535;
  htim12.Init.ClockDivision = TIM_CLOCKDIVISION_DIV1;
  htim12.Init.AutoReloadPreload = TIM_AUTORELOAD_PRELOAD_DISABLE;
  if (HAL_TIM_PWM_Init(&htim12) != HAL_OK)
  {
    Error_Handler();
  }
  sMasterConfig.MasterOutputTrigger = TIM_TRGO_RESET;
  sMasterConfig.MasterSlaveMode = TIM_MASTERSLAVEMODE_DISABLE;
  if (HAL_TIMEx_MasterConfigSynchronization(&htim12, &sMasterConfig) != HAL_OK)
  {
    Error_Handler();
  }
  sConfigOC.OCMode = TIM_OCMODE_PWM1;
  sConfigOC.Pulse = 0;
  sConfigOC.OCPolarity = TIM_OCPOLARITY_HIGH;
  sConfigOC.OCFastMode = TIM_OCFAST_DISABLE;
  if (HAL_TIM_PWM_ConfigChannel(&htim12, &sConfigOC, TIM_CHANNEL_2) != HAL_OK)
  {
    Error_Handler();
  }
  HAL_TIM_MspPostInit(&htim12);

}

static void MX_TIM13_Init(void)
{

  TIM_OC_InitTypeDef sConfigOC = {0};

  htim13.Instance = TIM13;
  htim13.Init.Prescaler = 0;
  htim13.Init.CounterMode = TIM_COUNTERMODE_UP;
  htim13.Init.Period = 65535;
  htim13.Init.ClockDivision = TIM_CLOCKDIVISION_DIV1;
  htim13.Init.AutoReloadPreload = TIM_AUTORELOAD_PRELOAD_DISABLE;
  if (HAL_TIM_Base_Init(&htim13) != HAL_OK)
  {
    Error_Handler();
  }
  if (HAL_TIM_PWM_Init(&htim13) != HAL_OK)
  {
    Error_Handler();
  }
  sConfigOC.OCMode = TIM_OCMODE_PWM1;
  sConfigOC.Pulse = 0;
  sConfigOC.OCPolarity = TIM_OCPOLARITY_HIGH;
  sConfigOC.OCFastMode = TIM_OCFAST_DISABLE;
  if (HAL_TIM_PWM_ConfigChannel(&htim13, &sConfigOC, TIM_CHANNEL_1) != HAL_OK)
  {
    Error_Handler();
  }
  HAL_TIM_MspPostInit(&htim13);

}

static void MX_TIM14_Init(void)
{

  TIM_OC_InitTypeDef sConfigOC = {0};

  htim14.Instance = TIM14;
  htim14.Init.Prescaler = 0;
  htim14.Init.CounterMode = TIM_COUNTERMODE_UP;
  htim14.Init.Period = 65535;
  htim14.Init.ClockDivision = TIM_CLOCKDIVISION_DIV1;
  htim14.Init.AutoReloadPreload = TIM_AUTORELOAD_PRELOAD_DISABLE;
  if (HAL_TIM_Base_Init(&htim14) != HAL_OK)
  {
    Error_Handler();
  }
  if (HAL_TIM_PWM_Init(&htim14) != HAL_OK)
  {
    Error_Handler();
  }
  sConfigOC.OCMode = TIM_OCMODE_PWM1;
  sConfigOC.Pulse = 0;
  sConfigOC.OCPolarity = TIM_OCPOLARITY_HIGH;
  sConfigOC.OCFastMode = TIM_OCFAST_DISABLE;
  if (HAL_TIM_PWM_ConfigChannel(&htim14, &sConfigOC, TIM_CHANNEL_1) != HAL_OK)
  {
    Error_Handler();
  }
  HAL_TIM_MspPostInit(&htim14);

}

static void MX_TIM15_Init(void)
{

  TIM_MasterConfigTypeDef sMasterConfig = {0};
  TIM_OC_InitTypeDef sConfigOC = {0};
  TIM_BreakDeadTimeConfigTypeDef sBreakDeadTimeConfig = {0};

  htim15.Instance = TIM15;
  htim15.Init.Prescaler = 0;
  htim15.Init.CounterMode = TIM_COUNTERMODE_UP;
  htim15.Init.Period = 65535;
  htim15.Init.ClockDivision = TIM_CLOCKDIVISION_DIV1;
  htim15.Init.RepetitionCounter = 0;
  htim15.Init.AutoReloadPreload = TIM_AUTORELOAD_PRELOAD_DISABLE;
  if (HAL_TIM_PWM_Init(&htim15) != HAL_OK)
  {
    Error_Handler();
  }
  sMasterConfig.MasterOutputTrigger = TIM_TRGO_RESET;
  sMasterConfig.MasterSlaveMode = TIM_MASTERSLAVEMODE_DISABLE;
  if (HAL_TIMEx_MasterConfigSynchronization(&htim15, &sMasterConfig) != HAL_OK)
  {
    Error_Handler();
  }
  sConfigOC.OCMode = TIM_OCMODE_PWM1;
  sConfigOC.Pulse = 0;
  sConfigOC.OCPolarity = TIM_OCPOLARITY_HIGH;
  sConfigOC.OCNPolarity = TIM_OCNPOLARITY_HIGH;
  sConfigOC.OCFastMode = TIM_OCFAST_DISABLE;
  sConfigOC.OCIdleState = TIM_OCIDLESTATE_RESET;
  sConfigOC.OCNIdleState = TIM_OCNIDLESTATE_RESET;
  if (HAL_TIM_PWM_ConfigChannel(&htim15, &sConfigOC, TIM_CHANNEL_1) != HAL_OK)
  {
    Error_Handler();
  }
  if (HAL_TIM_PWM_ConfigChannel(&htim15, &sConfigOC, TIM_CHANNEL_2) != HAL_OK)
  {
    Error_Handler();
  }
  sBreakDeadTimeConfig.OffStateRunMode = TIM_OSSR_DISABLE;
  sBreakDeadTimeConfig.OffStateIDLEMode = TIM_OSSI_DISABLE;
  sBreakDeadTimeConfig.LockLevel = TIM_LOCKLEVEL_OFF;
  sBreakDeadTimeConfig.DeadTime = 0;
  sBreakDeadTimeConfig.BreakState = TIM_BREAK_DISABLE;
  sBreakDeadTimeConfig.BreakPolarity = TIM_BREAKPOLARITY_HIGH;
  sBreakDeadTimeConfig.BreakFilter = 0;
  sBreakDeadTimeConfig.AutomaticOutput = TIM_AUTOMATICOUTPUT_DISABLE;
  if (HAL_TIMEx_ConfigBreakDeadTime(&htim15, &sBreakDeadTimeConfig) != HAL_OK)
  {
    Error_Handler();
  }
  HAL_TIM_MspPostInit(&htim15);

}

static void MX_TIM16_Init(void)
{

  TIM_OC_InitTypeDef sConfigOC = {0};
  TIM_BreakDeadTimeConfigTypeDef sBreakDeadTimeConfig = {0};

  htim16.Instance = TIM16;
  htim16.Init.Prescaler = 0;
  htim16.Init.CounterMode = TIM_COUNTERMODE_UP;
  htim16.Init.Period = 65535;
  htim16.Init.ClockDivision = TIM_CLOCKDIVISION_DIV1;
  htim16.Init.RepetitionCounter = 0;
  htim16.Init.AutoReloadPreload = TIM_AUTORELOAD_PRELOAD_DISABLE;
  if (HAL_TIM_Base_Init(&htim16) != HAL_OK)
  {
    Error_Handler();
  }
  if (HAL_TIM_PWM_Init(&htim16) != HAL_OK)
  {
    Error_Handler();
  }
  sConfigOC.OCMode = TIM_OCMODE_PWM1;
  sConfigOC.Pulse = 0;
  sConfigOC.OCPolarity = TIM_OCPOLARITY_HIGH;
  sConfigOC.OCNPolarity = TIM_OCNPOLARITY_HIGH;
  sConfigOC.OCFastMode = TIM_OCFAST_DISABLE;
  sConfigOC.OCIdleState = TIM_OCIDLESTATE_RESET;
  sConfigOC.OCNIdleState = TIM_OCNIDLESTATE_RESET;
  if (HAL_TIM_PWM_ConfigChannel(&htim16, &sConfigOC, TIM_CHANNEL_1) != HAL_OK)
  {
    Error_Handler();
  }
  sBreakDeadTimeConfig.OffStateRunMode = TIM_OSSR_DISABLE;
  sBreakDeadTimeConfig.OffStateIDLEMode = TIM_OSSI_DISABLE;
  sBreakDeadTimeConfig.LockLevel = TIM_LOCKLEVEL_OFF;
  sBreakDeadTimeConfig.DeadTime = 0;
  sBreakDeadTimeConfig.BreakState = TIM_BREAK_DISABLE;
  sBreakDeadTimeConfig.BreakPolarity = TIM_BREAKPOLARITY_HIGH;
  sBreakDeadTimeConfig.BreakFilter = 0;
  sBreakDeadTimeConfig.AutomaticOutput = TIM_AUTOMATICOUTPUT_DISABLE;
  if (HAL_TIMEx_ConfigBreakDeadTime(&htim16, &sBreakDeadTimeConfig) != HAL_OK)
  {
    Error_Handler();
  }
  HAL_TIM_MspPostInit(&htim16);

}

static void MX_UART4_Init(void)
{

  huart4.Instance = UART4;
  huart4.Init.BaudRate = 115200;
  huart4.Init.WordLength = UART_WORDLENGTH_8B;
  huart4.Init.StopBits = UART_STOPBITS_1;
  huart4.Init.Parity = UART_PARITY_NONE;
  huart4.Init.Mode = UART_MODE_TX_RX;
  huart4.Init.HwFlowCtl = UART_HWCONTROL_NONE;
  huart4.Init.OverSampling = UART_OVERSAMPLING_16;
  huart4.Init.OneBitSampling = UART_ONE_BIT_SAMPLE_DISABLE;
  huart4.Init.ClockPrescaler = UART_PRESCALER_DIV1;
  huart4.AdvancedInit.AdvFeatureInit = UART_ADVFEATURE_NO_INIT;
  if (HAL_UART_Init(&huart4) != HAL_OK)
  {
    Error_Handler();
  }
  if (HAL_UARTEx_SetTxFifoThreshold(&huart4, UART_TXFIFO_THRESHOLD_1_8) != HAL_OK)
  {
    Error_Handler();
  }
  if (HAL_UARTEx_SetRxFifoThreshold(&huart4, UART_RXFIFO_THRESHOLD_1_8) != HAL_OK)
  {
    Error_Handler();
  }
  if (HAL_UARTEx_DisableFifoMode(&huart4) != HAL_OK)
  {
    Error_Handler();
  }

}

static void MX_GPIO_Init(void)
{
  GPIO_InitTypeDef GPIO_InitStruct = {0};

  /* GPIO Ports Clock Enable */
  __HAL_RCC_GPIOE_CLK_ENABLE();
  __HAL_RCC_GPIOC_CLK_ENABLE();
  __HAL_RCC_GPIOH_CLK_ENABLE();
  __HAL_RCC_GPIOA_CLK_ENABLE();
  __HAL_RCC_GPIOB_CLK_ENABLE();
  __HAL_RCC_GPIOD_CLK_ENABLE();

  /*Configure GPIO pin Output Level */
  HAL_GPIO_WritePin(GPIOE, TIM1_CH3_PHASE_Pin|TIM1_CH4_PHASE_Pin|TIM2_CH1_PHASE_Pin|TIM8_CH4_PHASE_Pin
                          |TIM12_CH2_PHASE_Pin|TIM13_CH1_PHASE_Pin|TIM14_CH1_PHASE_Pin|TIM15_CH1_PHASE_Pin
                          |TIM1_CH1_PHASE_Pin|TIM1_CH2_PHASE_Pin, GPIO_PIN_RESET);

  /*Configure GPIO pin Output Level */
  HAL_GPIO_WritePin(GPIOC, TIM4_CH4_PHASE_Pin|TIM5_CH2_PHASE_Pin|TIM5_CH3_PHASE_Pin|TIM4_CH3_PHASE_Pin, GPIO_PIN_RESET);

  /*Configure GPIO pin Output Level */
  HAL_GPIO_WritePin(GPIOB, LED0_Pin|LED1_Pin|LED2_Pin|TIM4_CH1_PHASE_Pin
                          |TIM4_CH2_PHASE_Pin|SPI6_MUX_OE_n_Pin, GPIO_PIN_RESET);

  /*Configure GPIO pin Output Level */
  HAL_GPIO_WritePin(GPIOD, HRTIM_CHC1_PHASE_Pin|HRTIM_CHC2_PHASE_Pin|HRTIM_CHD1_PHASE_Pin|HRTIM_CHD2_PHASE_Pin
                          |TIM15_CH2_PHASE_Pin|TIM16_CH1_PHASE_Pin|HRTIM_CHA1_PHASE_Pin|HRTIM_CHA2_PHASE_Pin
                          |HRTIM_CHB1_PHASE_Pin|HRTIM_CHB2_PHASE_Pin, GPIO_PIN_RESET);

  /*Configure GPIO pin Output Level */
  HAL_GPIO_WritePin(ACTUATOR_ENABLE_MCU_GPIO_Port, ACTUATOR_ENABLE_MCU_Pin, GPIO_PIN_RESET);

  /*Configure GPIO pins : TIM1_CH3_PHASE_Pin TIM1_CH4_PHASE_Pin TIM2_CH1_PHASE_Pin TIM8_CH4_PHASE_Pin
                           TIM12_CH2_PHASE_Pin TIM13_CH1_PHASE_Pin TIM14_CH1_PHASE_Pin TIM15_CH1_PHASE_Pin
                           TIM1_CH1_PHASE_Pin TIM1_CH2_PHASE_Pin */
  GPIO_InitStruct.Pin = TIM1_CH3_PHASE_Pin|TIM1_CH4_PHASE_Pin|TIM2_CH1_PHASE_Pin|TIM8_CH4_PHASE_Pin
                          |TIM12_CH2_PHASE_Pin|TIM13_CH1_PHASE_Pin|TIM14_CH1_PHASE_Pin|TIM15_CH1_PHASE_Pin
                          |TIM1_CH1_PHASE_Pin|TIM1_CH2_PHASE_Pin;
  GPIO_InitStruct.Mode = GPIO_MODE_OUTPUT_PP;
  GPIO_InitStruct.Pull = GPIO_NOPULL;
  GPIO_InitStruct.Speed = GPIO_SPEED_FREQ_LOW;
  HAL_GPIO_Init(GPIOE, &GPIO_InitStruct);

  /*Configure GPIO pins : TIM4_CH4_PHASE_Pin TIM5_CH2_PHASE_Pin TIM5_CH3_PHASE_Pin TIM4_CH3_PHASE_Pin */
  GPIO_InitStruct.Pin = TIM4_CH4_PHASE_Pin|TIM5_CH2_PHASE_Pin|TIM5_CH3_PHASE_Pin|TIM4_CH3_PHASE_Pin;
  GPIO_InitStruct.Mode = GPIO_MODE_OUTPUT_PP;
  GPIO_InitStruct.Pull = GPIO_NOPULL;
  GPIO_InitStruct.Speed = GPIO_SPEED_FREQ_LOW;
  HAL_GPIO_Init(GPIOC, &GPIO_InitStruct);

  /*Configure GPIO pin : PC0 */
  GPIO_InitStruct.Pin = GPIO_PIN_0;
  GPIO_InitStruct.Mode = GPIO_MODE_ANALOG;
  GPIO_InitStruct.Pull = GPIO_NOPULL;
  HAL_GPIO_Init(GPIOC, &GPIO_InitStruct);

  /*Configure GPIO pins : LDC1_INTB_Pin LDC0_INTB_Pin */
  GPIO_InitStruct.Pin = LDC1_INTB_Pin|LDC0_INTB_Pin;
  GPIO_InitStruct.Mode = GPIO_MODE_INPUT;
  GPIO_InitStruct.Pull = GPIO_NOPULL;
  HAL_GPIO_Init(GPIOC, &GPIO_InitStruct);

  /*Configure GPIO pins : LED0_Pin LED1_Pin LED2_Pin TIM4_CH1_PHASE_Pin
                           TIM4_CH2_PHASE_Pin SPI6_MUX_OE_n_Pin */
  GPIO_InitStruct.Pin = LED0_Pin|LED1_Pin|LED2_Pin|TIM4_CH1_PHASE_Pin
                          |TIM4_CH2_PHASE_Pin|SPI6_MUX_OE_n_Pin;
  GPIO_InitStruct.Mode = GPIO_MODE_OUTPUT_PP;
  GPIO_InitStruct.Pull = GPIO_NOPULL;
  GPIO_InitStruct.Speed = GPIO_SPEED_FREQ_LOW;
  HAL_GPIO_Init(GPIOB, &GPIO_InitStruct);

  /*Configure GPIO pins : HRTIM_CHC1_PHASE_Pin HRTIM_CHC2_PHASE_Pin HRTIM_CHD1_PHASE_Pin HRTIM_CHD2_PHASE_Pin
                           TIM15_CH2_PHASE_Pin TIM16_CH1_PHASE_Pin HRTIM_CHA1_PHASE_Pin HRTIM_CHA2_PHASE_Pin
                           HRTIM_CHB1_PHASE_Pin HRTIM_CHB2_PHASE_Pin */
  GPIO_InitStruct.Pin = HRTIM_CHC1_PHASE_Pin|HRTIM_CHC2_PHASE_Pin|HRTIM_CHD1_PHASE_Pin|HRTIM_CHD2_PHASE_Pin
                          |TIM15_CH2_PHASE_Pin|TIM16_CH1_PHASE_Pin|HRTIM_CHA1_PHASE_Pin|HRTIM_CHA2_PHASE_Pin
                          |HRTIM_CHB1_PHASE_Pin|HRTIM_CHB2_PHASE_Pin;
  GPIO_InitStruct.Mode = GPIO_MODE_OUTPUT_PP;
  GPIO_InitStruct.Pull = GPIO_NOPULL;
  GPIO_InitStruct.Speed = GPIO_SPEED_FREQ_LOW;
  HAL_GPIO_Init(GPIOD, &GPIO_InitStruct);

  /*Configure GPIO pin : ACTUATOR_ENABLE_MCU_Pin */
  GPIO_InitStruct.Pin = ACTUATOR_ENABLE_MCU_Pin;
  GPIO_InitStruct.Mode = GPIO_MODE_OUTPUT_PP;
  GPIO_InitStruct.Pull = GPIO_NOPULL;
  GPIO_InitStruct.Speed = GPIO_SPEED_FREQ_LOW;
  HAL_GPIO_Init(ACTUATOR_ENABLE_MCU_GPIO_Port, &GPIO_InitStruct);

}

/* USER CODE BEGIN 4 */

void HAL_TIM_PeriodElapsedCallback(TIM_HandleTypeDef *htim)
{
		static int i=0;
		static int phase = 1;
		const double step = 0.8;// setpoint reference (arbitrary units)

		if (htim==&htim1){
		  i+=1;
		  if(i%ONESEC == TRUE)
		  {
			phase = -phase;
		  }
		  ref = phase*step;
		  ctrl_tmr_expired = TRUE;
	  }
}

static void control_update(double ref)
{
	// sign bit of the command fed to phase input on the h-bridge
	static int phase=GPIO_PIN_SET;
	static uint16_t dutycycle=0;
	double absref = 0;

	// calculate the dutycycle
	absref = fabs(ref); // duty cycle must be positive
	dutycycle = calc_dutycycle(absref,VSS);

	// Set the actuator direction
	if(ref < 0){
		phase = GPIO_PIN_RESET; // reverse direction
	} else {
		phase = GPIO_PIN_SET; //forward direction
	}

	//Timer 1 channels
	HAL_GPIO_WritePin(TIM1_CH1_PHASE_GPIO_Port, TIM1_CH1_PHASE_Pin, phase);
	TIM1->CCR1 = dutycycle;

	HAL_GPIO_WritePin(TIM1_CH2_PHASE_GPIO_Port, TIM1_CH2_PHASE_Pin, phase);
	TIM1->CCR2 = dutycycle;

	HAL_GPIO_WritePin(TIM1_CH3_PHASE_GPIO_Port, TIM1_CH3_PHASE_Pin, phase);
	TIM1->CCR3 = dutycycle;

	HAL_GPIO_WritePin(TIM1_CH4_PHASE_GPIO_Port, TIM1_CH4_PHASE_Pin, phase);
	TIM1->CCR4 = dutycycle;
	//End Timer 1
}

static uint16_t calc_dutycycle(double cmd, double vss)
{
	//------------------------------//
	//	@function calc_dutycycle(cmd, vss)
	//	@ param cmd command voltage
	//	@ param vss supply voltage
	//	@ return dutycycle

	// duty cycle variable
	uint16_t dc={0};

	dc = (uint16_t)(cmd/vss * (double)PERIOD);
	// keep the dutycycle within the period of the PWM signal
	if(dc>PERIOD) dc = PERIOD;

	return dc;
}

/* USER CODE END 4 */

void Error_Handler(void)
{
  __disable_irq();
  while (1)
  {
  }
}
